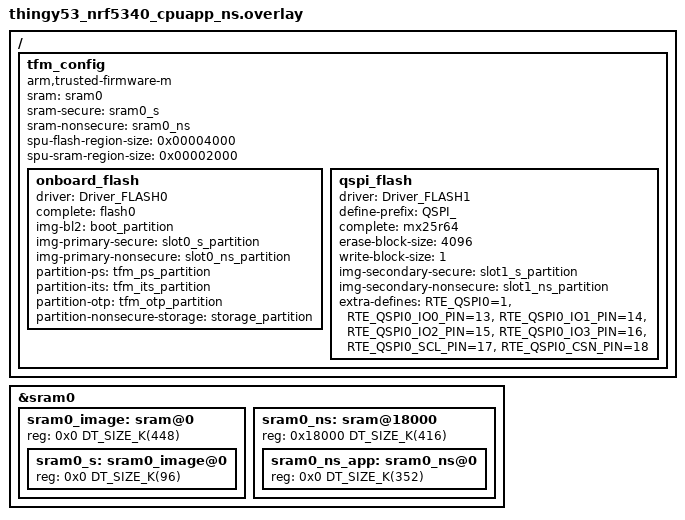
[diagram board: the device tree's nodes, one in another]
#include <common/nordic/infuse_nrf5340_cpuapp_ns.dtsi>
#include "thingy53_nrf5340_cpuapp_common.dtsi"

/* Allocate more memory to non-secure application */
/delete-node/ &sram0_s;
/delete-node/ &sram0_ns;

/ {
	tfm_config {
		compatible = "arm,trusted-firmware-m";
		sram = <&sram0>;
		sram-secure = <&sram0_s>;
		sram-nonsecure = <&sram0_ns>;
		spu-flash-region-size = <0x00004000>;
		spu-sram-region-size = <0x00002000>;

		onboard_flash {
			driver = "Driver_FLASH0";
			complete = <&flash0>;
			img-bl2 = <&boot_partition>;
			img-primary-secure = <&slot0_s_partition>;
			img-primary-nonsecure = <&slot0_ns_partition>;
			partition-ps = <&tfm_ps_partition>;
			partition-its = <&tfm_its_partition>;
			partition-otp = <&tfm_otp_partition>;
			partition-nonsecure-storage = <&storage_partition>;
		};

		qspi_flash {
			driver = "Driver_FLASH1";
			define-prefix = "QSPI_";
			complete = <&mx25r64>;
			erase-block-size = <4096>;
			write-block-size = <1>;
			img-secondary-secure = <&slot1_s_partition>;
			img-secondary-nonsecure = <&slot1_ns_partition>;
			/* Expected by Laird QSPI driver.
			 * Ideally driver would consume pinctrl values and
			 * these defines could be dropped.
			 */
			extra-defines =
				"RTE_QSPI0=1",
				"RTE_QSPI0_IO0_PIN=13",
				"RTE_QSPI0_IO1_PIN=14",
				"RTE_QSPI0_IO2_PIN=15",
				"RTE_QSPI0_IO3_PIN=16",
				"RTE_QSPI0_SCL_PIN=17",
				"RTE_QSPI0_CSN_PIN=18";
		};
	};
};

&sram0 {
	sram0_image: sram@0 {
		/* Secure + Nonsecure */
		reg = <0x0 DT_SIZE_K(448)>;
		ranges = <0x0 0x0 0x70000>;
		#address-cells = <1>;
		#size-cells = <1>;

		sram0_s: sram0_image@0 {
			/* Secure image memory */
			reg = <0x0 DT_SIZE_K(96)>;
		};
	};
	sram0_ns: sram@18000 {
		/* Non-Secure image memory */
		reg = <0x18000 DT_SIZE_K(416)>;
		ranges = <0x0 0x18000 DT_SIZE_K(416)>;
		#address-cells = <1>;
		#size-cells = <1>;

		sram0_ns_app: sram0_ns@0 {
			/* Non-Secure application memory */
			reg = <0x0 DT_SIZE_K(352)>;
		};
	};
};
